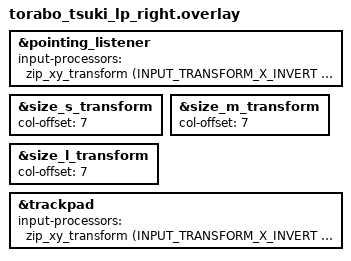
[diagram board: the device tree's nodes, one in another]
#define TORABO_TSUKI_LP_RIGHT 1

#include "torabo_tsuki_lp.dtsi"
#include <input/processors.dtsi>
#include <dt-bindings/zmk/input_transform.h>

&pointing_listener {
    input-processors = <&zip_xy_transform (INPUT_TRANSFORM_X_INVERT | INPUT_TRANSFORM_Y_INVERT)>;
};

&size_s_transform {
    col-offset = <7>;
};

&size_m_transform {
    col-offset = <7>;
};

&size_l_transform {
    col-offset = <7>;
};

/* 拡張トラックパッド（iqs7211e）専用の入力処理を定義して割り当てる */
&trackpad {
    // トラックパッド単体のX軸を反転。Y軸はトラックボールと同じにするなら反転、そのままなら未指定
    input-processors = <&zip_xy_transform (INPUT_TRANSFORM_X_INVERT | INPUT_TRANSFORM_Y_INVERT)>;
};
